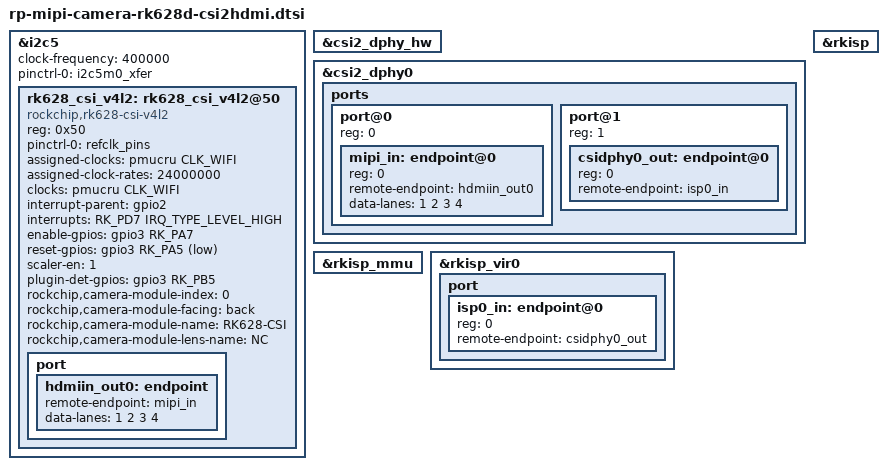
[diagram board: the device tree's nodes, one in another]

&i2c5 {
    clock-frequency = <400000>;
    status = "okay";
    pinctrl-0 = <&i2c5m0_xfer>;

    rk628_csi_v4l2: rk628_csi_v4l2@50 {
        status = "okay";
                reg = <0x50>;
        compatible = "rockchip,rk628-csi-v4l2";

                pinctrl-names = "default";
                pinctrl-0 = <&refclk_pins>;
                assigned-clocks = <&pmucru CLK_WIFI>;
                assigned-clock-rates = <24000000>;
                clocks = <&pmucru CLK_WIFI>;
                clock-names = "soc_24M";

                interrupt-parent = <&gpio2>;
                interrupts = <RK_PD7 IRQ_TYPE_LEVEL_HIGH>;
                enable-gpios = <&gpio3 RK_PA7 GPIO_ACTIVE_HIGH>;
                reset-gpios = <&gpio3 RK_PA5 GPIO_ACTIVE_LOW>;
         //hdcp-enable = <1>;
        scaler-en = <1>;

                   /*
            * If the hpd output level is inverted on the circuit,
                * the following configuration needs to be enabled.
            */

            /* hpd-output-inverted; */
            plugin-det-gpios = <&gpio3 RK_PB5 GPIO_ACTIVE_HIGH>;
            //power-gpios = <&gpio0 17 GPIO_ACTIVE_HIGH>;
            rockchip,camera-module-index = <0>;
            rockchip,camera-module-facing = "back";
            rockchip,camera-module-name = "RK628-CSI";
            rockchip,camera-module-lens-name = "NC";

        port {
                    hdmiin_out0: endpoint {
                            remote-endpoint = <&mipi_in>;
                            data-lanes = <1 2 3 4>;
                    };
            };
        };
};


&csi2_dphy_hw {
    status = "okay";
};

&csi2_dphy0 {
    status = "okay";
    ports {
        #address-cells = <1>;
        #size-cells = <0>;
        
        port@0 {
            reg = <0>;
            #address-cells = <1>;
            #size-cells = <0>;
            mipi_in: endpoint@0 {
                reg = <0>;
                remote-endpoint = <&hdmiin_out0>;
                data-lanes = <1 2 3 4>;
            };
        };

        port@1 {
            reg = <1>;
            #address-cells = <1>;
            #size-cells = <0>;
            csidphy0_out: endpoint@0 {
                reg = <0>;
                remote-endpoint = <&isp0_in>;
            };
        };
    };
};

&rkisp {
    status = "okay";
};

&rkisp_mmu {
    status = "okay";
};

&rkisp_vir0 {
    status = "okay";
    port {
        #address-cells = <1>;
        #size-cells = <0>;
        isp0_in: endpoint@0 {
            reg = <0>;
            remote-endpoint = <&csidphy0_out>;
        };
    };
};

